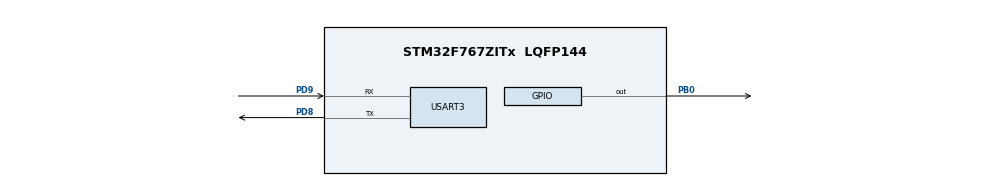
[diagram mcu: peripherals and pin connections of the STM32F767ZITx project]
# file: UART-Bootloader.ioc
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CORTEX_M7.default_mode_Activation=1
Mcu.Family=STM32F7
Mcu.Name=STM32F767ZITx
Mcu.Package=LQFP144
NVIC.PriorityGroup=NVIC_PRIORITYGROUP_4
PB0.Signal=GPIO_Output
PD8.Mode=Asynchronous
PD8.Signal=USART3_TX
PD9.Mode=Asynchronous
PD9.Signal=USART3_RX
ProjectManager.HeapSize=0x200
ProjectManager.StackSize=0x400
ProjectManager.TargetToolchain=STM32CubeIDE
RCC.HSE_VALUE=25000000
RCC.HSI_VALUE=16000000
RCC.LSE_VALUE=32768
RCC.USBFreq_Value=96000000
RCC.VCOOutputFreq_Value=192000000
USART3.VirtualMode-Asynchronous=VM_ASYNC
board=custom

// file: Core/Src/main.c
/* USER CODE BEGIN Header */
/**
  ******************************************************************************
  * @file           : main.c
  * @brief          : Main program body
  ******************************************************************************
  * @attention
  *
  * Copyright (c) 2024 STMicroelectronics.
  * All rights reserved.
  *
  * This software is licensed under terms that can be found in the LICENSE file
  * in the root directory of this software component.
  * If no LICENSE file comes with this software, it is provided AS-IS.
  *
  ******************************************************************************
  */
/* USER CODE END Header */
#include "main.h"

/* USER CODE BEGIN Includes */
#include <stdio.h>
/* USER CODE END Includes */

/* USER CODE BEGIN PM */
#define MAJOR 0		//Major Version Number
#define MINOR 1		//Minor Version Number
/* USER CODE END PM */

UART_HandleTypeDef huart3;

/* USER CODE BEGIN PV */
const uint8_t BL_Version[2] = { MAJOR, MINOR };
/* USER CODE END PV */

void SystemClock_Config(void);
static void MPU_Config(void);
static void MX_GPIO_Init(void);
static void MX_USART3_UART_Init(void);
/* USER CODE BEGIN PFP */
static void start_application ( void );
/* USER CODE END PFP */

int main(void)
{

  /* MPU Configuration--------------------------------------------------------*/
  MPU_Config();

  /* MCU Configuration--------------------------------------------------------*/

  /* Reset of all peripherals, Initializes the Flash interface and the Systick. */
  HAL_Init();

  /* Configure the system clock */
  SystemClock_Config();

  /* Initialize all configured peripherals */
  MX_GPIO_Init();
  MX_USART3_UART_Init();
  /* USER CODE BEGIN 2 */
  printf("Starting Bootloader (%d.%d)\n", BL_Version[0], BL_Version[1]);
  HAL_GPIO_WritePin( GPIOB, GPIO_PIN_0, GPIO_PIN_SET );
  HAL_Delay(2000);		// 2 Second Delay

  start_application();
  /* USER CODE END 2 */

  /* Infinite loop */
  while (1)
  {

  }
}

void SystemClock_Config(void)
{
  RCC_OscInitTypeDef RCC_OscInitStruct = {0};
  RCC_ClkInitTypeDef RCC_ClkInitStruct = {0};

  /** Configure the main internal regulator output voltage
  */
  __HAL_RCC_PWR_CLK_ENABLE();
  __HAL_PWR_VOLTAGESCALING_CONFIG(PWR_REGULATOR_VOLTAGE_SCALE3);

  /** Initializes the RCC Oscillators according to the specified parameters
  * in the RCC_OscInitTypeDef structure.
  */
  RCC_OscInitStruct.OscillatorType = RCC_OSCILLATORTYPE_HSI;
  RCC_OscInitStruct.HSIState = RCC_HSI_ON;
  RCC_OscInitStruct.HSICalibrationValue = RCC_HSICALIBRATION_DEFAULT;
  RCC_OscInitStruct.PLL.PLLState = RCC_PLL_NONE;
  if (HAL_RCC_OscConfig(&RCC_OscInitStruct) != HAL_OK)
  {
    Error_Handler();
  }

  /** Initializes the CPU, AHB and APB buses clocks
  */
  RCC_ClkInitStruct.ClockType = RCC_CLOCKTYPE_HCLK|RCC_CLOCKTYPE_SYSCLK
                              |RCC_CLOCKTYPE_PCLK1|RCC_CLOCKTYPE_PCLK2;
  RCC_ClkInitStruct.SYSCLKSource = RCC_SYSCLKSOURCE_HSI;
  RCC_ClkInitStruct.AHBCLKDivider = RCC_SYSCLK_DIV1;
  RCC_ClkInitStruct.APB1CLKDivider = RCC_HCLK_DIV1;
  RCC_ClkInitStruct.APB2CLKDivider = RCC_HCLK_DIV1;

  if (HAL_RCC_ClockConfig(&RCC_ClkInitStruct, FLASH_LATENCY_0) != HAL_OK)
  {
    Error_Handler();
  }
}

static void MX_USART3_UART_Init(void)
{

  huart3.Instance = USART3;
  huart3.Init.BaudRate = 115200;
  huart3.Init.WordLength = UART_WORDLENGTH_8B;
  huart3.Init.StopBits = UART_STOPBITS_1;
  huart3.Init.Parity = UART_PARITY_NONE;
  huart3.Init.Mode = UART_MODE_TX_RX;
  huart3.Init.HwFlowCtl = UART_HWCONTROL_NONE;
  huart3.Init.OverSampling = UART_OVERSAMPLING_16;
  huart3.Init.OneBitSampling = UART_ONE_BIT_SAMPLE_DISABLE;
  huart3.AdvancedInit.AdvFeatureInit = UART_ADVFEATURE_NO_INIT;
  if (HAL_UART_Init(&huart3) != HAL_OK)
  {
    Error_Handler();
  }

}

static void MX_GPIO_Init(void)
{
  GPIO_InitTypeDef GPIO_InitStruct = {0};

  /* GPIO Ports Clock Enable */
  __HAL_RCC_GPIOB_CLK_ENABLE();
  __HAL_RCC_GPIOD_CLK_ENABLE();

  /*Configure GPIO pin Output Level */
  HAL_GPIO_WritePin(GPIOB, GPIO_PIN_0, GPIO_PIN_RESET);

  /*Configure GPIO pin : PB0 */
  GPIO_InitStruct.Pin = GPIO_PIN_0;
  GPIO_InitStruct.Mode = GPIO_MODE_OUTPUT_PP;
  GPIO_InitStruct.Pull = GPIO_NOPULL;
  GPIO_InitStruct.Speed = GPIO_SPEED_FREQ_LOW;
  HAL_GPIO_Init(GPIOB, &GPIO_InitStruct);

}

/* USER CODE BEGIN 4 */
/**
  * @brief Print the characters to UART (printf).
  * @retval int
  */
#ifdef __GNUC__
  /* With GCC, small printf (option LD Linker->Libraries->Small printf
     set to 'Yes') calls __io_putchar() */
int __io_putchar(int ch)
#else
int fputc(int ch, FILE *f)
#endif /* __GNUC__ */
{
  /* Place your implementation of fputc here */
  /* e.g. write a character to the UART3 and Loop until the end of transmission */
  HAL_UART_Transmit(&huart3, (uint8_t *)&ch, 1, HAL_MAX_DELAY);

  return ch;
}

static void start_application ( void )
{
	printf("Starting Application\n");

	void (*app_reset_handler) (void) = (void*) ( *(volatile uint32_t *) (0x08040000 + 4));

	// To set stack address manually (for some microcontrollers)
	// __set_MSP( ( *(volatile uint32_t *) 0x08000000) );

	HAL_GPIO_WritePin( GPIOB, GPIO_PIN_0, GPIO_PIN_RESET );		//Green LED OFF
	app_reset_handler();
}
/* USER CODE END 4 */

 /* MPU Configuration */

void MPU_Config(void)
{
  MPU_Region_InitTypeDef MPU_InitStruct = {0};

  /* Disables the MPU */
  HAL_MPU_Disable();

  /** Initializes and configures the Region and the memory to be protected
  */
  MPU_InitStruct.Enable = MPU_REGION_ENABLE;
  MPU_InitStruct.Number = MPU_REGION_NUMBER0;
  MPU_InitStruct.BaseAddress = 0x0;
  MPU_InitStruct.Size = MPU_REGION_SIZE_4GB;
  MPU_InitStruct.SubRegionDisable = 0x87;
  MPU_InitStruct.TypeExtField = MPU_TEX_LEVEL0;
  MPU_InitStruct.AccessPermission = MPU_REGION_NO_ACCESS;
  MPU_InitStruct.DisableExec = MPU_INSTRUCTION_ACCESS_DISABLE;
  MPU_InitStruct.IsShareable = MPU_ACCESS_SHAREABLE;
  MPU_InitStruct.IsCacheable = MPU_ACCESS_NOT_CACHEABLE;
  MPU_InitStruct.IsBufferable = MPU_ACCESS_NOT_BUFFERABLE;

  HAL_MPU_ConfigRegion(&MPU_InitStruct);
  /* Enables the MPU */
  HAL_MPU_Enable(MPU_PRIVILEGED_DEFAULT);

}

void Error_Handler(void)
{
  __disable_irq();
  while (1)
  {
  }
}
